# tviic2d6mddr register map
Vendor: Cypress Semiconductor; Series: tviic2d6mddr; File version: 1.0
CPU: CM7 r0p1, little endian, MPU, FPU, VTOR, 3 interrupt priority bits
Registers are 32-bit, read-write, reset 0x0 unless marked. A register's access mark holds for its fields unless they carry their own. Offsets are from the block's base; [hi:lo] are bit positions; lines under a group give offsets from that group; {n}, {i} and the like mark numbered series; 'fields as' and 'values as' point back to an identical list.

## VIDEOSS0 (part 11 of 18) — Video and Graphics Subsystem IP
Base 0x40A00000
0x80000 VIDEOIO group — Video I/O Core
  0x20000 DISENG0 group — Display Engine
    0x2000 FRAMEGEN0 group — Frame Generator
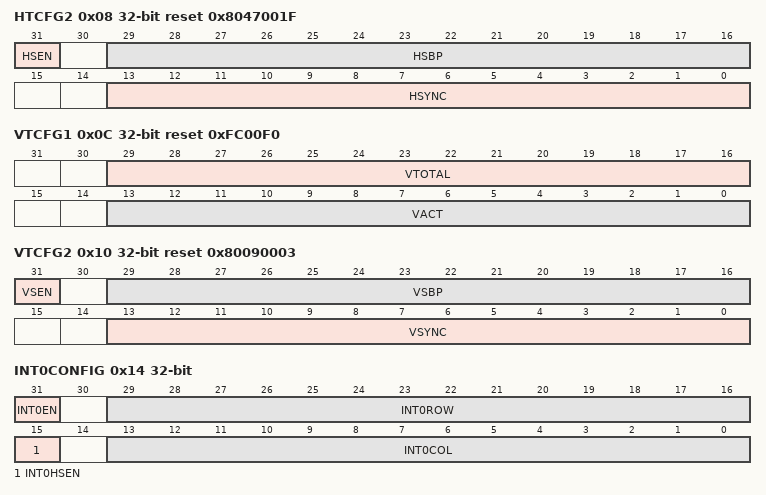
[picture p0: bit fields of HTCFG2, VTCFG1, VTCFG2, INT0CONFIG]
      0x08 HTCFG2 reset 0x8047001F — FrameGen Horizontal Timing Config Register 2
        [31] HSEN — Enables generation of HSYNC pulse.
        [29:16] HSBP — Width of HSYNC pulse plus width of horizontal back porch in pixels. (Set value +1 is the width of HSYNC pulse plus width of horizontal back porch) Hsbp shall be greater or equal than Hsync. Note: Valid setup for horizontal video timing contains parameters Hact, Htotal, Hsbp and, if enabled, Hsync.
        [13:0] HSYNC — Width of HSYNC pulse in pixels. (Set value +1 is the width of HSYNC pulse) HSYNC is of zero width if HsEn==0. Note: Valid setup for horizontal video timing contains parameters Hact, Htotal, Hsbp and, if enabled, Hsync.
      0x0C VTCFG1 reset 0xFC00F0 — FrameGen Vertical Timing Config Register 1
        [29:16] VTOTAL — Total vertical size of frame in lines. (Set value +1 is the total vertical size of frame) Vtotal shall be greater or equal than Vact + Vsbp. Note: Valid setup for vertical video timing contains parameters Vact, Vtotal, Vsbp and, if enabled, Vsync.
        [13:0] VACT — Vertical size of active display area in lines. Vact shall be greater or equal than 4. Note: Valid setup for vertical video timing contains parameters Vact, Vtotal, Vsbp and, if enabled, Vsync.
      0x10 VTCFG2 reset 0x80090003 — FrameGen Vertical Timing Config Register 2
        [31] VSEN — Enables generation of VSYNC pulse.
        [29:16] VSBP — Width of VSYNC pulse plus width of vertical back porch in lines. (Set value +1 is the width of VSYNC pulse plus width of vertical back porch) Vsbp shall be greater or equal than Vsync. Note: Valid setup for vertical video timing contains parameters Vact, Vtotal, Vsbp and, if enabled, Vsync.
        [13:0] VSYNC — Width of VSYNC pulse in lines. (Set value +1 is the width of VSYNC pulse) VSYNC is of zero width if VsEn==0. Note: Valid setup for vertical video timing contains parameters Vact, Vtotal, Vsbp and, if enabled, Vsync.
      0x14 INT0CONFIG — Coordinates of the trigger point for generation of the Int0 interrupt signal
        [31] INT0EN — Enables Int0.
        [29:16] INT0ROW — Specifies on which row of the display raster the Int0 signal is triggered (1 .. Int0Row .. VTOTAL). Adaptive display timing must be taken into account when defining Int0Row (1 .. Int0Row .. VTOTAL_MIN).
        [15] INT0HSEN — When enabled, Int0Row setting is ignored so that the interrupt occurs every line at position given by Int0Col.
        [13:0] INT0COL — Specifies on which column of the display raster the Int0 signal is triggered (1 .. Int0Col .. HTOTAL). Adaptive display timing must be taken into account when defining Int0Col (1 .. Int0Col .. HTOTAL_MIN).
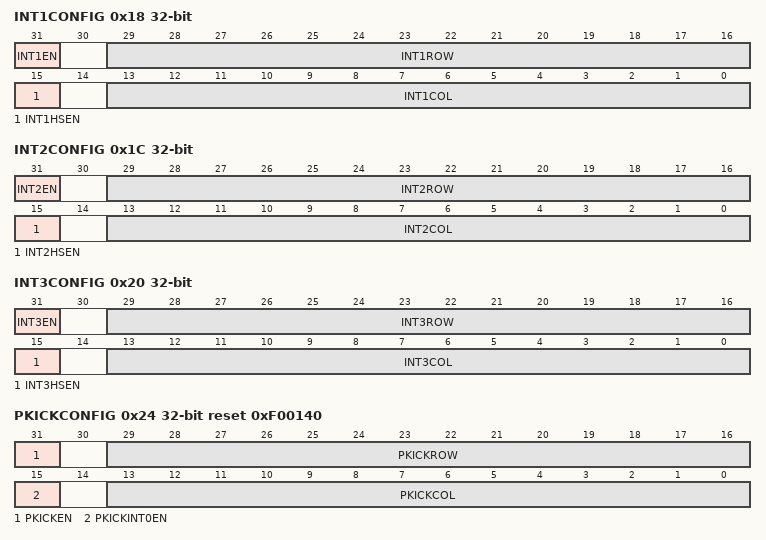
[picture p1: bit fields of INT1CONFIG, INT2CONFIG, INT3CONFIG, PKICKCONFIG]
      0x18 INT1CONFIG — Coordinates of the trigger point for generation of the Int1 interrupt signal
        [31] INT1EN — Enables Int1 (irq[1]).
        [29:16] INT1ROW — Specifies on which row of the display raster the Int1 signal is triggered (1 .. Int1Row .. VTOTAL). Adaptive display timing must be taken into account when defining Int1Row (1 .. Int1Row .. VTOTAL_MIN).
        [15] INT1HSEN — When enabled, Int1Row setting is ignored so that the interrupt occurs every line at position given by Int1Col.
        [13:0] INT1COL — Specifies on which column of the display raster the Int1 signal is triggered (1 .. Int1Col .. HTOTAL). Adaptive display timing must be taken into account when defining Int1Col (1 .. Int1Col .. HTOTAL_MIN).
      0x1C INT2CONFIG — Coordinates of the trigger point for generation of the Int2 interrupt signal
        [31] INT2EN — Enables Int2.
        [29:16] INT2ROW — Specifies on which row of the display raster the Int2 signal is triggered (1 .. Int2Row .. VTOTAL). Adaptive display timing must be taken into account when defining Int2Row (1 .. Int2Row .. VTOTAL_MIN).
        [15] INT2HSEN — When enabled, Int2Row setting is ignored so that the interrupt occurs every line at position given by Int2Col.
        [13:0] INT2COL — Specifies on which column of the display raster the Int2 signal is triggered (1 .. Int2Col .. HTOTAL). Adaptive display timing must be taken into account when defining Int2Col (1 .. Int2Col .. HTOTAL_MIN).
      0x20 INT3CONFIG — Coordinates of the trigger point for generation of the Int3 interrupt signal
        [31] INT3EN — Enables Int3.
        [29:16] INT3ROW — Specifies on which row of the display raster the Int3 signal is triggered (1 .. Int3Row .. VTOTAL). Adaptive display timing must be taken into account when defining Int3Row (1 .. Int3Row .. VTOTAL_MIN).
        [15] INT3HSEN — When enabled, Int3Row setting is ignored so that the interrupt occurs every line at position given by Int3Col.
        [13:0] INT3COL — Specifies on which column of the display raster the Int3 signal is triggered (1 .. Int3Col .. HTOTAL). Adaptive display timing must be taken into account when defining Int3Col (1 .. Int3Col .. HTOTAL_MIN).
      0x24 PKICKCONFIG reset 0xF00140 — Coordinates of the trigger point for generation of the primary kick signal
        [31] PKICKEN — Enables pkick signal.
        [29:16] PKICKROW — Specifies on which row of the display raster the pkick signal is triggered (1 .. PKickRow .. VTOTAL). Adaptive display timing must be taken into account when defining PKickRow (1 .. PKickRow .. VTOTAL_MIN).
        [15] PKICKINT0EN — If enabled, maps the primary kick signal (pkick) on the interrupt pin int0. Overrides int0en.
        [13:0] PKICKCOL — Specifies on which column of the display raster the pkick signal is triggered (1 .. PKickCol .. HTOTAL). Adaptive display timing must be taken into account when defining PKickCol (1 .. PKickCol .. HTOTAL_MIN).
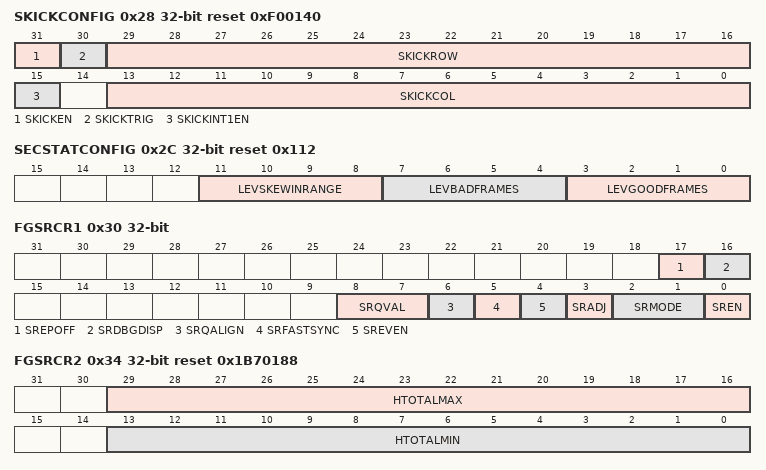
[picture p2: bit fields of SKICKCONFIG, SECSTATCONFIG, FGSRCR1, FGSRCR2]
      0x28 SKICKCONFIG reset 0xF00140 — Coordinates of the trigger point for generation of the secondary kick signal
        [31] SKICKEN — Enables generation of internal skick signal.
        [30] SKICKTRIG — Select source for skick generation.
          0=INTERNAL (Use internal skick signal, trigger point defined by SKickRow and SKickCol.); 1=EXTERNAL (Use external skick input as trigger.)
        [29:16] SKICKROW — Specifies on which row of the display raster the skick signal is triggered (1 .. SKickRow .. VTOTAL). Adaptive display timing must be taken into account when defining SKickRow (1 .. SKickRow .. VTOTAL_MIN).
        [15] SKICKINT1EN — If enabled, maps the secondary kick signal (skick) on the interrupt pin int1. Overrides int1en.
        [13:0] SKICKCOL — Specifies on which column of the display raster the skick signal is triggered (1 .. SKickCol .. HTOTAL). Adaptive display timing must be taken into account when defining SKickCol (1 .. SKickCol .. HTOTAL_MIN).
      0x2C SECSTATCONFIG reset 0x112 — Configuration register for controlling the behavior of the SecSyncStat field in the FgSecChStat register.
        [11:8] LEVSKEWINRANGE — Number of continuous frames the measured skew value shall be within the range defined by SyncRangeLow and SyncRangeHigh. If this condition is true, additionally LevGoodFrames valid frames must be processed before the status line of the sec. channel and the SecSyncStat status field goes to 1 indicating synchronized status. Value of 0 is not allowed.
        [7:4] LEVBADFRAMES — Not used.
        [3:0] LEVGOODFRAMES — Number of continuous correct frames that must be processed before SecSyncStat field goes 1 (in sync). Value of 0 is not allowed.
      0x30 FGSRCR1 — FrameGen Skew Regulation Control Register 1.
        [17] SREPOFF — Disables the skew Extrapolation in blanking.
        [16] SRDBGDISP — If enabled, the pixels are displayed that are read from FIFO when secondary channel is not in sync yet. Otherwise constant color is displayed in unsynchronized state.
        [8:7] SRQVAL — If SRQAlign is enabled, this field determines the fixed value of the two LSB bits of HTOTAL. Note: This has impact on the settings for Htotal, HtotalMin and HtotalMax.
          0=ZERO (Fixed two LSB values of HTOTAL are 0b00.); 1=ONE (Fixed two LSB values of HTOTAL are 0b01.); 2=TWO (Fixed two LSB values of HTOTAL are 0b10.); 3=THREE (Fixed two LSB values of HTOTAL are 0b11.)
        [6] SRQALIGN — Enables alignment of HTOTAL to be a multiple of 4. Overrides SREven field. Program field SRQVal for the desired value of the two LSB bits of HTOTAL.
        [5] SRFASTSYNC — Fast Synchronization Mode. Frame Generator is started synchronized to frame timing on secondary channel when switching FgEn from 0 to 1. This allows fast locking of skew regulation.
        [4] SREVEN — Total line length HTOTAL is even when SRAdj is enabled. Note: This has impact on the settings for Htotal, HtotalMin and HtotalMax.
        [3] SRADJ — Enables line length adjustment for HTOTAL. If SRQAlign=0, SREven determines whether HTOTAL has odd (SREven=0) or even (SrEven=1) number of pixels. If SRQAlign=1, SRQVal determines the value of the two LSB bits of HTOTAL.
        [2:1] SRMODE — Skew Control Operating Mode.
          0=OFF (Skew Regulation is off.); 1=HREG (Horizontal regulation enabled.); 2=VREG (Vertical regulation enabled.); 3=BOTH (Both regulation modes are enabled.)
        [0] SREN — If enabled, skew control for secondary channel is active. If disabled, skew control for secondary channel is in fetch mode. Fetch mode: secondary channel fetches frames and can intentionally produce a backstall via setting sbusy signal to active. This mode is intended to fetch frames from memory via a stallable pipeline, like the primary interface. No timing adaption of frames takes place in this mode.
      0x34 FGSRCR2 reset 0x1B70188 — FrameGen Skew Regulation Control Register 2
        [29:16] HTOTALMAX — Maximum value of htotal when horizontal regulation is enabled. (Set value +1 is the maximum value of htotal) HTotalMax must be greater or equal Htotal. Note: If SRAdj==1 then HtotalMax[0] shall be equal to the value of SREven.
        [13:0] HTOTALMIN — Minimum value of htotal when horizontal regulation is enabled. (Set value +1 is the minimum value of htotal, must be greater or equal Hsbp + Hactive) HTotalMin must be smaller or equal Htotal. Note: If SRAdj==1 then HtotalMin[0] shall be equal to the value of SREven.
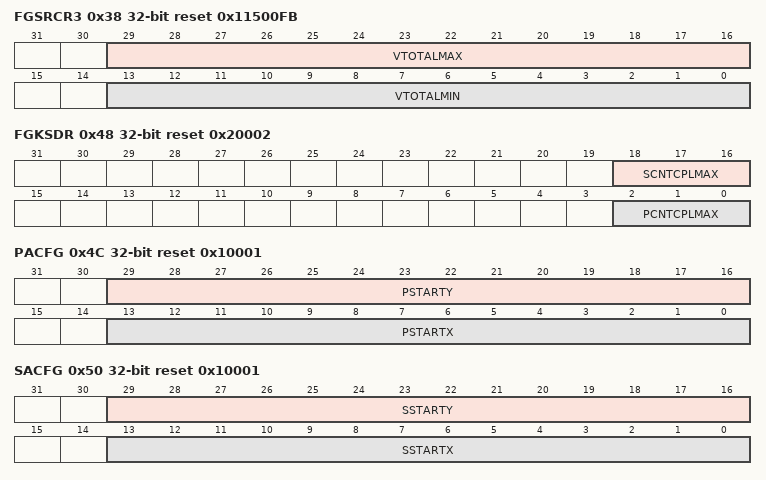
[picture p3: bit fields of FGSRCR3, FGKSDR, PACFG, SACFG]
      0x38 FGSRCR3 reset 0x11500FB — FrameGen Skew Regulation Control Register 3
        [29:16] VTOTALMAX — Maximum value of vtotal when vertical regulation is enabled. (Set value +1 is the maximum value of vtotal)
        [13:0] VTOTALMIN — Minimum value of vtotal when vertical regulation is enabled. (Set value +1 is the minimum value of vtotal, must be greater or equal Vsbp + Vactive + 1)
      0x3C FGSRCR4 reset 0xC8 — FrameGen Skew Regulation Control Register 4
        [28:0] TARGETSKEW — Horizontal target skew value for horizontal and vertical skew regulation (signed value). (format is signed integer)
      0x40 FGSRCR5 — FrameGen Skew Regulation Control Register 5
        [28:0] SYNCRANGELOW — Sync range of horizontal and vertical skew regulation. Lower value (signed value). If skew stays within programmed sync range, frame status is assumed synchronized. (format is signed integer)
      0x44 FGSRCR6 reset 0x190 — FrameGen Skew Regulation Control Register 6
        [28:0] SYNCRANGEHIGH — Sync range of horizontal and vertical skew regulation. Upper value (signed value). If skew stays within programmed sync range, frame status is assumed synchronized. (format is signed integer)
      0x48 FGKSDR reset 0x20002 — FrameGen Kick System Debug Register
        [18:16] SCNTCPLMAX — Maximum Value for spendcnt_cpl_s complementary secondary kick counter. Do not change!
        [2:0] PCNTCPLMAX — Maximum Value for ppendcnt_cpl_s complementary primary kick counter. Do not change!
      0x4C PACFG reset 0x10001 — FrameGen Primary Area Config Register 1 (shadowed)
        [29:16] PSTARTY — Primary screen upper left corner, y component. Counts from 1. Pstarty = 0 is not allowed. Primary screen shall not overlap the last column/ last row of the total frame defined by Htotal/ Vtotal.
        [13:0] PSTARTX — Primary screen upper left corner, x component. Counts from 1. Pstartx = 0 is not allowed. Primary screen shall not overlap the last column/ last row of the total frame defined by Htotal/ Vtotal.
      0x50 SACFG reset 0x10001 — FrameGen Secondary Area Config Register 1 (shadowed)
        [29:16] SSTARTY — Secondary screen upper left corner, y component. Counts from 1 . Sstarty = 0 is not allowed. Secondary screen shall not overlap the last column/ last row of the total frame defined by Htotal/ Vtotal. When skew regulation feature is enabled, the secondary screen shall not overlap the active display area defined by Hact and Vact.
        [13:0] SSTARTX — Secondary screen upper left corner, x component. Counts from 1 . Sstartx = 0 is not allowed. Secondary screen shall not overlap the last column/ last row of the total frame defined by Htotal/ Vtotal. When skew regulation feature is enabled, the secondary screen shall not overlap the active display area defined by Hact and Vact.
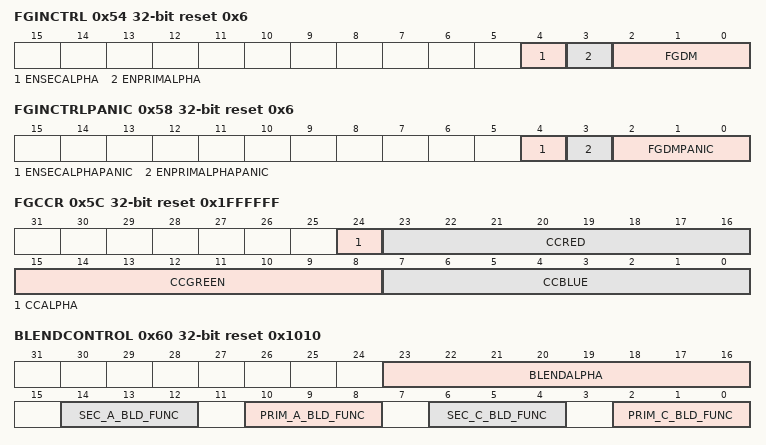
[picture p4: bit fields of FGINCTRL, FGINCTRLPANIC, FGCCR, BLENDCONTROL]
      0x54 FGINCTRL reset 0x6 — FrameGen Input Control Register (shadowed)
        [4] ENSECALPHA — When enabled, alpha plane of secondary channel is considered for screen composition. If the alpha component of the current pixel is 255, this pixel is opaque. Otherwise this pixel is transparent. Setting this field to 1 has no effect, when FgDm == BLEND.
        [3] ENPRIMALPHA — When enabled, alpha plane of primary channel is considered for screen composition. If the alpha component of the current pixel is 255, this pixel is opaque. Otherwise this pixel is transparent. Setting this field to 1 has no effect, when FgDm == BLEND.
        [2:0] FGDM — Frame Generator Display Mode.
          0=BLACK (Black color background is shown on the whole screen area.); 1=CONSTCOL (Programmable constant color is shown in the active area and black color in the blanking area.); 2=PRIM (Primary input only is shown.); 3=SEC (Secondary input only is shown.); 4=PRIM_ON_TOP (Both inputs overlaid with primary on top.); 5=SEC_ON_TOP (Both inputs overlaid with secondary on top.); 6=TEST (White color background with test pattern is shown in the active area and black color in the blanking area.); 7=BLEND (Blending of the mode PRIM with the mode SEC.)
      0x58 FGINCTRLPANIC reset 0x6 — FrameGen Input Control Panic Register (shadowed)
        [4] ENSECALPHAPANIC — When enabled, alpha plane of secondary channel is considered for screen composition. If the alpha component of the current pixel is 255, this pixel is opaque. Otherwise this pixel is transparent. Setting this field to 1 has no effect, when FgDmPanic == BLEND.
        [3] ENPRIMALPHAPANIC — When enabled, alpha plane of primary channel is considered for screen composition. If the alpha component of the current pixel is 255, this pixel is opaque. Otherwise this pixel is transparent. Setting this field to 1 has no effect, when FgDmPanic == BLEND.
        [2:0] FGDMPANIC — Frame Generator Display Mode.
          values as VIDEOIO.DISENG0.FRAMEGEN0.FGINCTRL.FGDM
      0x5C FGCCR reset 0x1FFFFFF — FrameGen Constant Color Register (shadowed)
        [24] CCALPHA — Constant color - alpha value. In case of blending the value of 1 will be extended to 0xff.
        [23:16] CCRED — Constant color - red component.
        [15:8] CCGREEN — Constant color - green component.
        [7:0] CCBLUE — Constant color - blue component.
      0x60 BLENDCONTROL reset 0x1010 — Options for blend operations. (shadowed)
        [23:16] BLENDALPHA — Constant alpha value, used for constant alpha blending
        [14:12] SEC_A_BLD_FUNC — Secondary (overlay) input alpha blending function
          0=ZERO (Aout = Ain * 0); 1=ONE (Aout = Ain * 1); 2=PRIM_ALPHA (Aout = Ain * ALPHA_prim); 3=ONE_MINUS_PRIM_ALPHA (Aout = Ain * (1 - ALPHA_prim)); 4=SEC_ALPHA (Aout = Ain * ALPHA_sec); 5=ONE_MINUS_SEC_ALPHA (Aout = Ain * (1 - ALPHA_sec)); 6=CONST_ALPHA (Aout = Ain * ALPHA_const); 7=ONE_MINUS_CONST_ALPHA (Aout = Ain * (1 - ALPHA_const))
        [10:8] PRIM_A_BLD_FUNC — Primary (background) input alpha blending function
          values as SEC_A_BLD_FUNC
        [6:4] SEC_C_BLD_FUNC — Secondary (overlay) input color blending function
          0=ZERO (Cout = Cin * 0); 1=ONE (Cout = Cin * 1); 2=PRIM_ALPHA (Cout = Cin * ALPHA_prim); 3=ONE_MINUS_PRIM_ALPHA (Cout = Cin * (1 - ALPHA_prim)); 4=SEC_ALPHA (Cout = Cin * ALPHA_sec); 5=ONE_MINUS_SEC_ALPHA (Cout = Cin * (1 - ALPHA_sec)); 6=CONST_ALPHA (Cout = Cin * ALPHA_const); 7=ONE_MINUS_CONST_ALPHA (Cout = Cin * (1 - ALPHA_const))
        [2:0] PRIM_C_BLD_FUNC — Primary (background) input color blending function
          values as SEC_C_BLD_FUNC
      0x64 FGENABLE — FrameGen Enable Register
        [0] FGEN — Frame Generator Enable. Note: For loading the shadow registers at start-up of FrameGen unit write the FgSlr.ShdTokGen field immediately before writing this field.
      0x68 FGSLR wo reset not defined — FrameGen Shadow Load Register
        [0] SHDTOKGEN — Generate shadow load token. Can be used to load shadow register in this and/or all subsequent units up to the next token end point.
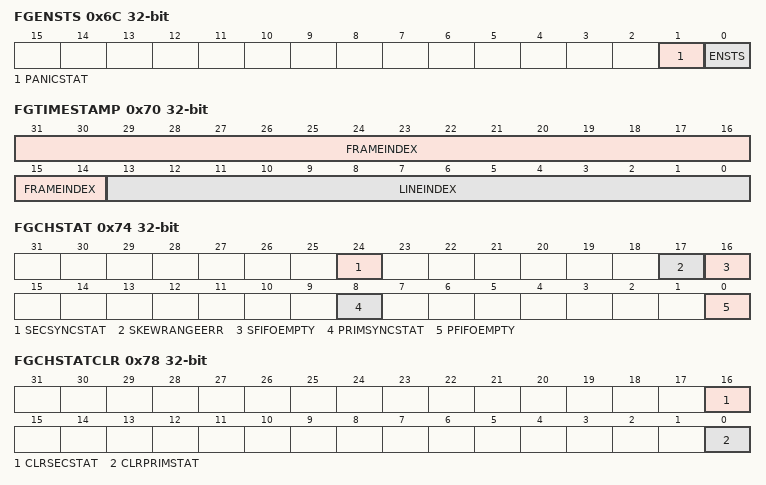
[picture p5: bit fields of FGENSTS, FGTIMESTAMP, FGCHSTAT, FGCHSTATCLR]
      0x6C FGENSTS ro — FrameGen Enable Status Register
        [1] PANICSTAT — Current status of panic mode (0=normal operation mode, 1=panic mode; not locked).
        [0] ENSTS — Indicates the current operating mode of the frame generator. EnSts = 0 means frame generator is disabled. EnSts = 1 means frame generator is enabled. In contrast to the FgEn field of the FgEnable register this bit goes only 0 when all pending frames are processed.
      0x70 FGTIMESTAMP ro — Time stamp status.
        [31:14] FRAMEINDEX — Index of the output frame that is currently generated (starts with 0 after reset for first output frame). Wraps around to 0 when maximum value is reached.
        [13:0] LINEINDEX — Index of the output line that is currently generated (starts with 0 for first active output line).
      0x74 FGCHSTAT ro — FrameGen Channel Status Register
        [24] SECSYNCSTAT — Current status secondary channel synchronization (0 = out of sync, 1 = in sync; not locked).
        [17] SKEWRANGEERR — The secondary channel skew value has run out of the limit defined by SyncRangeLow and SyncRangeHigh. (bit locked when 1, clear by using ClrSecStat).
        [16] SFIFOEMPTY — Read request to empty secondary pixel FIFO detected. (bit locked when 1, clear by using ClrSecStat).
        [8] PRIMSYNCSTAT — Current status primary channel synchronization (0 = out of sync (frame tearing), 1 = in sync (normal operation); not locked).
        [0] PFIFOEMPTY — Read request to empty primary pixel FIFO detected. (Bit locked when 1, clear by using ClrPrimStat).
      0x78 FGCHSTATCLR wo reset not defined — FrameGen Channel Status Clear Register
        [16] CLRSECSTAT — Clears SFifoEmpty and SkewRangeErr in FgChStat register.
        [0] CLRPRIMSTAT — Clears PFifoEmpty in FgChStat register.
      0x7C FGSKEWMON ro — FrameGen Skew Monitor Register for Secondary Channel Skew Control
        [28:0] SKEWMON — Current skew value monitor for secondary channel skew control. Updated with hlast. (For debugging purposes only).
      0x80 FGSFIFOMIN ro reset not defined — FrameGen Secondary FIFO Min Fill Register
        [10:0] SFIFOMIN — Shows the minimal fill level of the secondary channel pixel FIFO. (For debugging purposes only).
      0x84 FGSFIFOMAX ro reset not defined — FrameGen Secondary FIFO Max Fill Register
        [10:0] SFIFOMAX — Shows the maximal fill level of the secondary channel pixel FIFO. (For debugging purposes only).
      0x88 FGSFIFOFILLCLR wo reset not defined — FrameGen Secondary FIFO Fill Clear Register
        [0] SFIFOFILLCLR — Write for clearing register FgSFifoMin and FgSFifoMax. (For debugging purposes only).
      0x8C FGSREPD ro — FrameGen Skew Regulation ExtraPolation Debug Register
        [28:0] EPVAL — Calculated value for line skew extrapolation in blanking. Updated with condition 'hlast AND vlast'. (For debugging purposes only)
      0x90 FGSRFTD ro — FrameGen Skew Regulation Frame Total Debug Register
        [27:0] FRTOT — Measured value for frame total measured in display clock cycles. Updated with condition 'hlast AND vlast' when first FrTot value is valid. (For debugging purposes only)
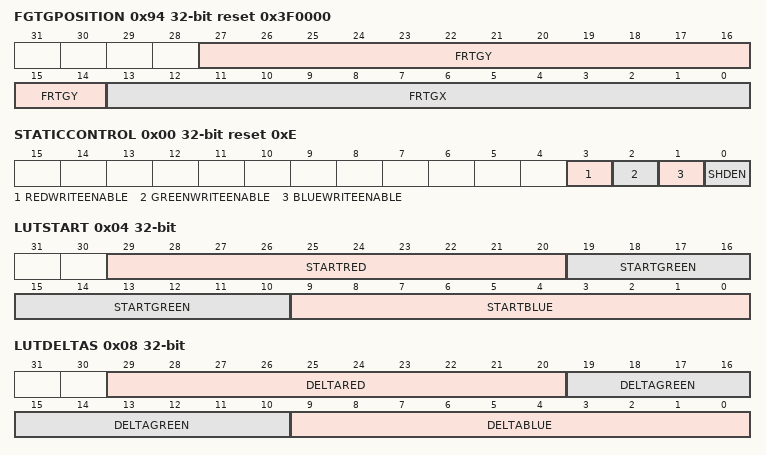
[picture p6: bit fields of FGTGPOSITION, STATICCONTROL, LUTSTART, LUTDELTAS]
      0x94 FGTGPOSITION ro reset 0x3F0000 — Current (x,y) positions of the timing generator register in FrameGen timing generator.
        [27:14] FRTGY — Coordinated line position starting from VACT inside a total frame generated in timing generator in display clock cycles. (For debugging purposes only)
        [13:0] FRTGX — Coordinated pixel position starting from HACT inside a total line generated in timing generator in display clock cycles. (For debugging purposes only)
    0x2400 GAMMACOR0 group — Gamma Correction Unit 1
      0x00 STATICCONTROL reset 0xE — Static control settings.
        [3] REDWRITEENABLE — Write enable for the red color sampling point entries.
        [2] GREENWRITEENABLE — Write enable for the green color sampling point entries.
        [1] BLUEWRITEENABLE — Write enable for the blue color sampling point entries.
        [0] SHDEN — Enables shadowing of all RWS type registers (0=write_through, 1=shadowed).
      0x04 LUTSTART wo — Start values for look-up table programming.
        [29:20] STARTRED — Start value for red or luma (Y) channel. (format is unsigned integer)
        [19:10] STARTGREEN — Start value for green or chroma (U) channel. (format is unsigned integer)
        [9:0] STARTBLUE — Start value for blue or chroma (V) channel. (format is unsigned integer)
      0x08 LUTDELTAS wo reset not defined — Delta values for look-up table programming.
        [29:20] DELTARED — Delta value for red or luma (Y) channel. (format is signed integer)
        [19:10] DELTAGREEN — Delta value for green or chroma (U) channel. (format is signed integer)
        [9:0] DELTABLUE — Delta value for blue or chroma (V) channel. (format is signed integer)
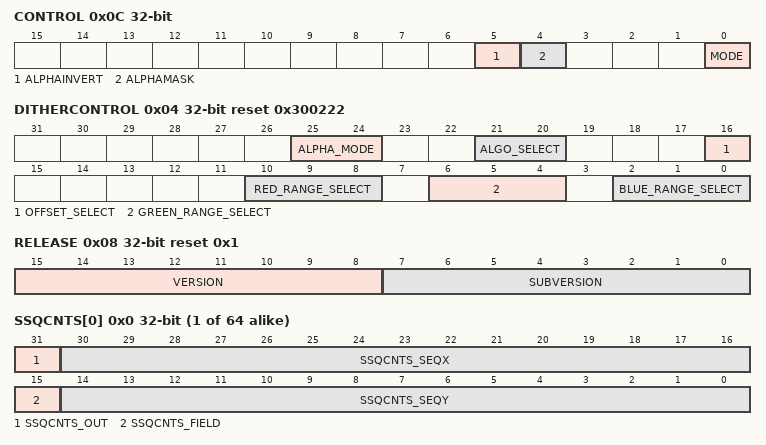
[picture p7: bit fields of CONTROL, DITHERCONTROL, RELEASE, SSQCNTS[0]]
      0x0C CONTROL — Dynamic control settings.
        [5] ALPHAINVERT — Value 1 inverts the effect of the alpha mask mode when enabled (pixels with alpha value greater or equal 0.5 are by-passed).
        [4] ALPHAMASK — Value 1 enables the alpha mask mode. In this mode all pixels with an alpha value smaller than 0.5 are by-passed unchanged.
        [0] MODE — Operation mode for gamma correction unit
          0=NEUTRAL (Module in neutral mode, input data is bypassed to the output.); 1=GAMMACOR (Module in gamma correction mode.)
    0x2800 DITHER0 group — Dither Unit
      0x00 CONTROL — Dither Unit common control.
        [0] MODE — Mode which switches Dither Unit on/off. (format is unsigned integer)
          0=NEUTRAL (Neutral mode. Pixels by-pass the Dither Unit, all other settings are ignored.); 1=ACTIVE (Dither Unit is active.)
      0x04 DITHERCONTROL reset 0x300222 — Dither Unit processing control.
        [25:24] ALPHA_MODE — Enables/disables that dithering can be switched by alpha bit. (format is unsigned integer)
          0=DISABLE (The alpha bit is not considered.); 1=ENABLE_BY1 (Red, green and blue components are only dithered, if the alpha bit is 1.); 2=ENABLE_BY0 (Red, green and blue components are only dithered, if the alpha bit is 0.)
        [21:20] ALGO_SELECT — The number of output colors that can virtually be displayed by dithering is slightly lower than the number of physical input colors. This field selects how the mapping is done. (format is unsigned integer)
          1=NO_CORRECTION (Best possible resolution for most dark colors. Adds a diminutive offset to overall image brightness.); 2=BRIGHTNESS_CORRECTION (Preserves overall image brightness. Cannot resolve most dark and most bright colors. All codes in-between are distributed perfectly smooth.); 3=CONTRAST_CORRECTION (Preserves overall image brightness. Best possible distribution of color codes over complete range.)
        [16] OFFSET_SELECT — Selects the method how the dither offset is calculated. (format is unsigned integer)
          0=OFFS_SPATIAL (Offset is a bayer matrix value, which is selected according to pixel frame position.); 1=OFFS_TEMPORAL (Offset is the sum from a bayer matrix value, which is selected according to pixel frame position, and a value from a regular sequence, which changes each frame.)
        [10:8] RED_RANGE_SELECT — Mode which sets the reduction of component widths. (format is unsigned integer)
          2=RED_10TO8 (Reduces red component width from 10 bit to 8bit.); 3=RED_10TO7 (Reduces red component width from 10 bit to 7bit.); 4=RED_10TO6 (Reduces red component width from 10 bit to 6bit.); 5=RED_10TO5 (Reduces red component width from 10 bit to 5bit.)
        [6:4] GREEN_RANGE_SELECT — Mode which sets the reduction of component widths. (format is unsigned integer)
          2=GREEN_10TO8 (Reduces green component width from 10 bit to 8bit.); 3=GREEN_10TO7 (Reduces green component width from 10 bit to 7bit.); 4=GREEN_10TO6 (Reduces green component width from 10 bit to 6bit.); 5=GREEN_10TO5 (Reduces green component width from 10 bit to 5bit.)
        [2:0] BLUE_RANGE_SELECT — Mode which sets the reduction of component widths. (format is unsigned integer)
          2=BLUE_10TO8 (Reduces blue component width from 10 bit to 8bit.); 3=BLUE_10TO7 (Reduces blue component width from 10 bit to 7bit.); 4=BLUE_10TO6 (Reduces blue component width from 10 bit to 6bit.); 5=BLUE_10TO5 (Reduces blue component width from 10 bit to 5bit.)
      0x08 RELEASE ro reset 0x1 — Dither Unit release.
        [15:8] VERSION — Dither Unit version. (format is unsigned integer)
        [7:0] SUBVERSION — Dither Unit subversion. (format is unsigned integer)
    0x3000 TCON0 group — Timing Controller
      {0x0+4l} SSQCNTS[{l}] (l=0..63) reset not defined — The 64 Sequencer Position Definitions registers define the X/Y scan positions of the sequencers, hold their output value and assign the sequencer to an odd/even field
        [31] SSQCNTS_OUT — This bit holds the value (0,1) to be output when the X/Y scan position is reached.
        [30:16] SSQCNTS_SEQX — X scan position
        [15] SSQCNTS_FIELD — Field 0b=odd field, 1b=even field
        [14:0] SSQCNTS_SEQY — Y scan position
      0x400 SSQCYCLE — This bitfield sets the sequencer cycle length. The value set here -1 is the number of sequencer cycles
        [5:0] SSQCYCLE — Sequencer cycle length (number -1) of sequencer cycles
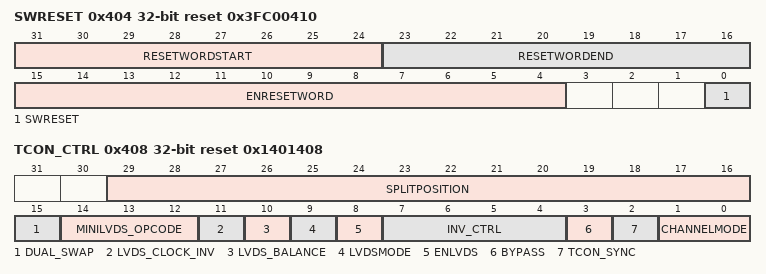
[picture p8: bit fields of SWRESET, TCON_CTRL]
      0x404 SWRESET reset 0x3FC00410 — TCON Software Reset - Reset all tcon registers except configuration registers. Detailed description in specification document Note 1/ if tsig[11] pulse=n*pixel_period, (n-1)*0xFF will be blended between ResetWordStart and ResetWordEnd into miniLVDS stream Note 2/ if( EnResetWord=0) Reset-Pulse (ResetWordStart,ResetWordEnd) won't be blended into miniLVDS stream. Pixels will be transferred unchanged
        [31:24] RESETWORDSTART — 8-Bits value, that will be blended on rising edge of tsig[11] into miniLVDS stream
        [23:16] RESETWORDEND — 8-Bits value, that will be blended on falling edge of tsig[11] into miniLVDS stream
        [15:4] ENRESETWORD — Enable to blend ResetWord into miniLVDS stream EnResetWord[5-0] mapped to enable Blending Reset Pulse to [RLV5.RLV0]. EnResetWord[11-6] mapped to enable Blending Reset Pulse to [LLV5.LLV0].
        [0] SWRESET — Software reset
          0=OPERATION (operation mode); 1=SWRESET (So long SWReset = 0x1 tcon is in 'SW reset state' and it is released by internal logic (SWReset is released and end of frame arrived), read 0b reset not active 1b reset active (that means NO pixel of video frame is excepted until 'SW reset state' is released))
      0x408 TCON_CTRL reset 0x1401408 — TCON Control register
        [29:16] SPLITPOSITION — Index of first column of right display half when ChannelMode is DUAL_SPLIT. SplitPosition and (Hact - SplitPosition) must be less or equal than half of the max supported active frame width. If SplitPosition is greater than (Hact - SplitPosition), then Htotal must be greater than 2*SplitPosition; else Htotal must be greater than 2*(Hact - SplitPosition). Once setting a SplitPosition, data_en is needed. The SplitPosition must be even.
        [15] DUAL_SWAP — pixels of lower/upper channel can be swapped if tcon operates in DUAL-mode (include LVDS/miniLVDS) no effect in SINGLE-mode
          1=SWAP (swapping pixels between lower-channel and upper-channel); 0=NON_SWAP (NON-swapping pixels between lower-channel and upper-channel)
        [14:12] MINILVDS_OPCODE — Operation mode of MiniLVDS
          0=MODE_3PAIRS (MiniLVDS operates in 6 and 8 bit data, three pairs); 1=MODE_4PAIRS (Not Implemented); 2=MODE_5PAIRS (Not Implemented); 3=MODE_6PAIRS (MiniLVDS operates in 6 and 8 bit data, six pairs); {v}=RSVD{v-3} (N/A) (v=4..7)
        [11] LVDS_CLOCK_INV — Inversion the polarity of lvds clock in OpenLDI Mode
          1=INV (Invert LVDS Clock); 0=NON_INV (NON-Invert LVDS Clock)
        [10] LVDS_BALANCE — Operation mode of LVDS-OpenLDI
          1=BALANCED (LVDS operates in 24 bits Balanced Mode); 0=UNBALANCED (LVDS operates in 24 bits Unbalanced Mode)
        [9] LVDSMODE — Selection the LVDS Mode if EnLVDS = ENABLE_LVDS
          1=MINI_LVDS; 0=LVDS (LVDS Mode, refer to OpenLDI)
        [8] ENLVDS — Enable LVDS Mode
          1=ENABLE_LVDS (Enable LVDS , TTL and RSDS are disable); 0=DISABLE_LVDS (Disable LVDS, Enable TTL and RSDS)
        [7:4] INV_CTRL — Minimize the toggle rate of tcon output for display panel, that supports data inversion control. Otherwise set Inv_Ctrl = 0. Valid for all channels . Inv_Ctrl does not effect any function on LVDS-Output.
          0=DISABLE (Disable inversion control); 1=RGB_2_BITS (Enable inversion control for number of RGB-Bits = 2); 2=RGB_4_BITS (Enable inversion control for number of RGB-Bits = 4); 3=RGB_6_BITS (Enable inversion control for number of RGB-Bits = 6); 4=RGB_8_BITS (Enable inversion control for number of RGB-Bits = 8); 5=RGB_10_BITS (Enable inversion control for number of RGB-Bits = 10); 6=RGB_12_BITS (Enable inversion control for number of RGB-Bits = 12); 7=RGB_14_BITS (Enable inversion control for number of RGB-Bits = 14); 8=RGB_16_BITS (Enable inversion control for number of RGB-Bits = 16); 9=RGB_18_BITS (Enable inversion control for number of RGB-Bits = 18); 10=RGB_20_BITS (Enable inversion control for number of RGB-Bits = 20); 11=RGB_22_BITS (Enable inversion control for number of RGB-Bits = 22); 12=RGB_24_BITS (Enable inversion control for number of RGB-Bits = 24); 13=RSVD1 (N/A); 14=RSVD2 (N/A); 15=RSVD3 (N/A)
        [3] BYPASS — Bypassing synchronization
          0=TCON_MODE (tcon operation mode); 1=BYPASS_MODE (tcon in Bypass mode. input pixel and its sync-signals are bypassed to tcon-output)
        [2] TCON_SYNC — Select synchronization between hsync/vsync and hlast/vlast
          0=H_VLAST (tcon timing generator synchronized to hlast, vlast); 1=H_VSYNC (tcon timing generator synchronized to hsync, vsync where horizontal synchronization is synchronized at the falling edge of hsync)
        [1:0] CHANNELMODE — Selects one of tcon operation modes, SINGLE, DUAL_INTERLEAVED or DUAL_SPLIT. If MiniLVDS operation is selected (EnLVDS = ENABLE_LVDS and LVDSMode = Mini_LVDS), tcon operates in MiniLVDS mode, independent of ChannelMode programming. SplitPosition must be specified in MiniLVDS operation in DUAL_INTERLEAVED or DUAL_SPLIT mode, the horizontal parameter of signal generator have to set twice as they are specified in the panel-specification (panel 320, tsig_start 0, tsig_stop 320 on DUAL-Mode tsig_start 0, tsig_stop 640 ... (SplitPosition is automatically adjusted) )
          0=SINGLE (Single pixel mode. Both channels channel are active at full pixel clock. If bitmap of both panels are the same, both panels are identical); 1=DUAL_INTERLEAVED (Dual pixel mode. Both channels are active at half the pixel clock. 1st channel drives display columns with even and 2nd one with odd index.); 2=DUAL_SPLIT (Dual pixel mode. Both channels are active at half the pixel clock. 1st channel drives the left and 2nd one the right half of the display. Note data_en is needed in this mode)
